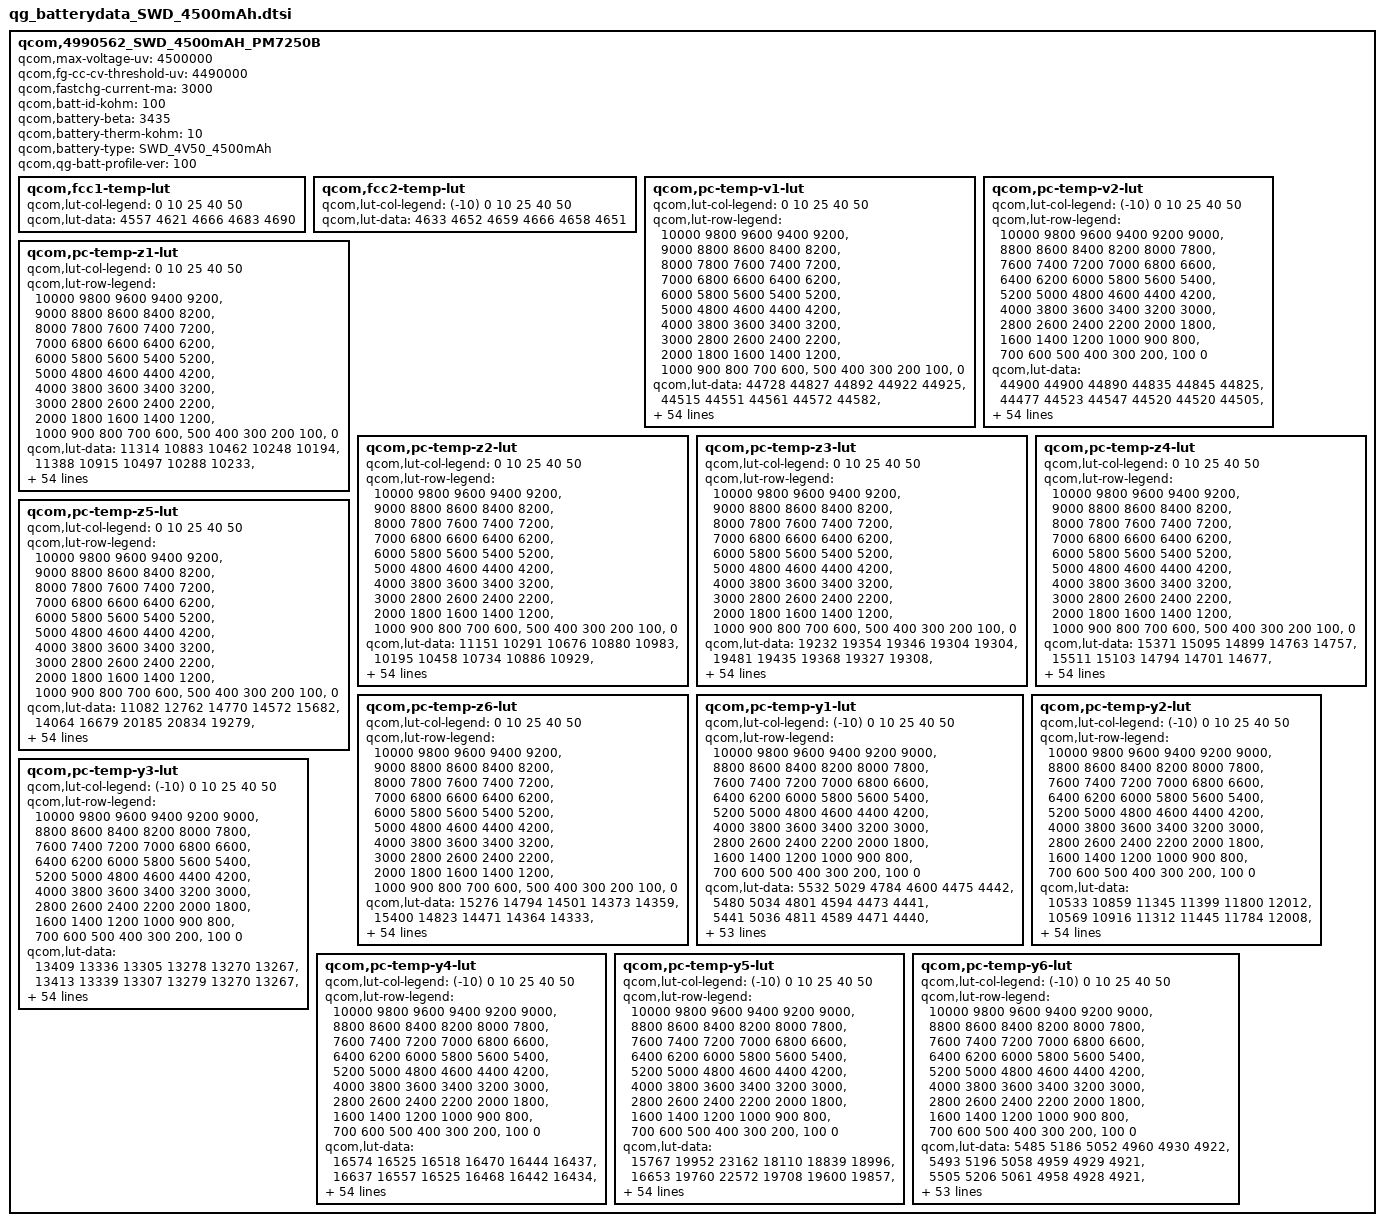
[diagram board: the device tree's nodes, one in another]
/* Copyright (c) 2018, The Linux Foundation. All rights reserved.
 *
 * This program is free software; you can redistribute it and/or modify
 * it under the terms of the GNU General Public License version 2 and
 * only version 2 as published by the Free Software Foundation.
 *
 * This program is distributed in the hope that it will be useful,
 * but WITHOUT ANY WARRANTY; without even the implied warranty of
 * MERCHANTABILITY or FITNESS FOR A PARTICULAR PURPOSE.  See the
 * GNU General Public License for more details.
 */

qcom,4990562_SWD_4500mAH_PM7250B {
    /* 4990562_SWD_4500mAH_PM7250B_averaged_MasterSlave_Jan11th2021 */
    qcom,max-voltage-uv = <4500000>;
    qcom,fg-cc-cv-threshold-uv = <4490000>;
    qcom,fastchg-current-ma = <3000>;
    qcom,batt-id-kohm = <100>;
    qcom,battery-beta = <3435>;
    qcom,battery-therm-kohm = <10>;
    qcom,battery-type = "SWD_4V50_4500mAh";
    qcom,qg-batt-profile-ver = <100>;

	qcom,fcc1-temp-lut {
		qcom,lut-col-legend = <0 10 25 40 50>;
		qcom,lut-data = <4557 4621 4666 4683 4690>;
	};

	qcom,fcc2-temp-lut {
		qcom,lut-col-legend = <(-10) 0 10 25 40 50>;
		qcom,lut-data = <4633 4652 4659 4666 4658 4651>;
	};

	qcom,pc-temp-v1-lut {
		qcom,lut-col-legend = <0 10 25 40 50>;
		qcom,lut-row-legend = <10000 9800 9600 9400 9200>,
			<9000 8800 8600 8400 8200>,
			<8000 7800 7600 7400 7200>,
			<7000 6800 6600 6400 6200>,
			<6000 5800 5600 5400 5200>,
			<5000 4800 4600 4400 4200>,
			<4000 3800 3600 3400 3200>,
			<3000 2800 2600 2400 2200>,
			<2000 1800 1600 1400 1200>,
			<1000 900 800 700 600>,
			<500 400 300 200 100>,
			<0>;
		qcom,lut-data = <44728 44827 44892 44922 44925>,
			<44515 44551 44561 44572 44582>,
			<44325 44352 44340 44336 44342>,
			<44136 44173 44149 44142 44146>,
			<43939 43986 43963 43959 43958>,
			<43734 43786 43763 43761 43762>,
			<43515 43577 43556 43553 43559>,
			<43278 43350 43335 43335 43346>,
			<43034 43109 43095 43102 43116>,
			<42787 42863 42847 42861 42875>,
			<42537 42611 42597 42614 42630>,
			<42291 42359 42345 42361 42380>,
			<42047 42110 42095 42111 42131>,
			<41807 41863 41846 41862 41885>,
			<41574 41623 41603 41618 41643>,
			<41347 41389 41367 41381 41404>,
			<41129 41163 41137 41149 41170>,
			<40922 40948 40916 40924 40943>,
			<40716 40741 40701 40706 40723>,
			<40509 40539 40497 40497 40512>,
			<40297 40346 40310 40308 40320>,
			<40059 40123 40111 40110 40123>,
			<39792 39819 39852 39864 39883>,
			<39560 39529 39571 39589 39614>,
			<39374 39346 39355 39366 39389>,
			<39216 39205 39182 39184 39201>,
			<39089 39071 39032 39027 39039>,
			<38984 38939 38898 38889 38899>,
			<38884 38818 38778 38766 38774>,
			<38782 38709 38667 38651 38657>,
			<38687 38611 38566 38545 38547>,
			<38606 38522 38473 38447 38446>,
			<38533 38442 38387 38356 38352>,
			<38467 38371 38310 38273 38265>,
			<38405 38305 38244 38200 38188>,
			<38350 38247 38186 38135 38117>,
			<38304 38196 38128 38064 38036>,
			<38264 38154 38074 37987 37941>,
			<38204 38097 38009 37902 37840>,
			<38102 38001 37916 37804 37737>,
			<37978 37880 37801 37694 37628>,
			<37842 37750 37676 37571 37499>,
			<37686 37602 37532 37430 37351>,
			<37494 37423 37362 37262 37187>,
			<37327 37250 37199 37110 37041>,
			<37244 37139 37096 37024 36963>,
			<37205 37109 37074 37003 36946>,
			<37171 37085 37055 36988 36931>,
			<37139 37065 37032 36969 36909>,
			<37075 37002 36954 36861 36783>,
			<36793 36716 36654 36536 36448>,
			<36323 36251 36187 36065 35980>,
			<35707 35640 35580 35460 35373>,
			<34871 34806 34757 34625 34543>,
			<33564 33504 33486 33347 33264>,
			<30000 30000 30000 30000 30000>;
	};

	qcom,pc-temp-v2-lut {
		qcom,lut-col-legend = <(-10) 0 10 25 40 50>;
		qcom,lut-row-legend = <10000 9800 9600 9400 9200 9000>,
			<8800 8600 8400 8200 8000 7800>,
			<7600 7400 7200 7000 6800 6600>,
			<6400 6200 6000 5800 5600 5400>,
			<5200 5000 4800 4600 4400 4200>,
			<4000 3800 3600 3400 3200 3000>,
			<2800 2600 2400 2200 2000 1800>,
			<1600 1400 1200 1000 900 800>,
			<700 600 500 400 300 200>,
			<100 0>;
		qcom,lut-data = <44900 44900 44890 44835 44845 44825>,
			<44477 44523 44547 44520 44520 44505>,
			<44126 44209 44256 44246 44238 44226>,
			<43864 43974 44030 44026 44011 44000>,
			<43666 43795 43854 43847 43827 43815>,
			<43464 43609 43669 43658 43635 43623>,
			<43239 43399 43462 43447 43423 43413>,
			<43006 43177 43244 43224 43201 43191>,
			<42767 42943 43011 42990 42968 42960>,
			<42519 42695 42764 42743 42723 42717>,
			<42270 42446 42515 42494 42476 42471>,
			<42019 42194 42263 42243 42227 42223>,
			<41767 41943 42012 41993 41978 41976>,
			<41507 41697 41765 41745 41732 41731>,
			<41253 41455 41521 41501 41490 41490>,
			<41065 41224 41284 41264 41254 41254>,
			<40939 41001 41052 41033 41024 41023>,
			<40779 40788 40826 40808 40801 40800>,
			<40441 40598 40614 40592 40586 40587>,
			<40018 40401 40400 40379 40375 40379>,
			<39724 40139 40163 40166 40172 40177>,
			<39498 39811 39909 39952 39974 39979>,
			<39283 39523 39656 39716 39748 39757>,
			<39064 39284 39395 39429 39460 39474>,
			<38857 39073 39159 39171 39194 39209>,
			<38665 38890 38975 38992 39015 39030>,
			<38487 38729 38819 38845 38871 38886>,
			<38353 38582 38678 38709 38737 38753>,
			<38251 38449 38549 38583 38614 38629>,
			<38168 38324 38431 38469 38501 38514>,
			<38102 38201 38322 38365 38397 38408>,
			<38047 38088 38220 38269 38301 38310>,
			<37992 38008 38126 38178 38213 38221>,
			<37938 37947 38038 38093 38133 38143>,
			<37884 37896 37959 38009 38046 38052>,
			<37825 37856 37888 37930 37948 37938>,
			<37761 37817 37822 37847 37844 37812>,
			<37688 37770 37756 37745 37729 37689>,
			<37607 37715 37690 37633 37608 37565>,
			<37518 37643 37611 37531 37499 37453>,
			<37420 37537 37508 37441 37407 37361>,
			<37307 37405 37387 37330 37295 37250>,
			<37166 37238 37243 37196 37159 37112>,
			<37014 37050 37089 37056 37024 36973>,
			<36885 36886 36923 36915 36880 36833>,
			<36786 36810 36867 36880 36853 36807>,
			<36746 36777 36842 36866 36839 36792>,
			<36707 36740 36817 36841 36818 36772>,
			<36659 36694 36770 36792 36779 36733>,
			<36564 36584 36649 36629 36653 36588>,
			<36330 36270 36324 36251 36283 36194>,
			<35894 35758 35793 35707 35763 35674>,
			<35273 35083 35109 34994 35090 34998>,
			<34428 34147 34168 33993 34168 34081>,
			<33164 32741 32782 32549 32901 32768>,
			<30762 29516 29512 29514 29512 29512>;
	};

	qcom,pc-temp-z1-lut {
		qcom,lut-col-legend = <0 10 25 40 50>;
		qcom,lut-row-legend = <10000 9800 9600 9400 9200>,
			<9000 8800 8600 8400 8200>,
			<8000 7800 7600 7400 7200>,
			<7000 6800 6600 6400 6200>,
			<6000 5800 5600 5400 5200>,
			<5000 4800 4600 4400 4200>,
			<4000 3800 3600 3400 3200>,
			<3000 2800 2600 2400 2200>,
			<2000 1800 1600 1400 1200>,
			<1000 900 800 700 600>,
			<500 400 300 200 100>,
			<0>;
		qcom,lut-data = <11314 10883 10462 10248 10194>,
			<11388 10915 10497 10288 10233>,
			<11383 10916 10487 10285 10231>,
			<11375 10901 10478 10281 10230>,
			<11360 10889 10471 10278 10229>,
			<11335 10882 10464 10275 10227>,
			<11316 10874 10459 10272 10225>,
			<11304 10860 10452 10269 10223>,
			<11293 10842 10446 10266 10221>,
			<11283 10831 10440 10263 10220>,
			<11273 10825 10436 10261 10219>,
			<11262 10821 10432 10259 10218>,
			<11243 10815 10428 10258 10217>,
			<11229 10810 10425 10257 10216>,
			<11227 10810 10422 10256 10215>,
			<11229 10811 10421 10255 10216>,
			<11226 10812 10420 10254 10216>,
			<11218 10805 10420 10254 10216>,
			<11211 10796 10419 10254 10216>,
			<11212 10793 10419 10254 10216>,
			<11215 10795 10420 10255 10217>,
			<11214 10795 10422 10255 10218>,
			<11210 10795 10423 10256 10218>,
			<11208 10795 10424 10257 10220>,
			<11206 10795 10427 10258 10221>,
			<11204 10796 10432 10260 10222>,
			<11205 10798 10437 10262 10223>,
			<11208 10801 10440 10263 10224>,
			<11211 10806 10442 10265 10226>,
			<11216 10814 10445 10267 10227>,
			<11221 10821 10448 10269 10229>,
			<11224 10822 10451 10272 10230>,
			<11225 10816 10454 10274 10232>,
			<11226 10813 10458 10276 10234>,
			<11224 10815 10462 10278 10235>,
			<11222 10819 10467 10281 10237>,
			<11223 10824 10471 10284 10238>,
			<11227 10832 10476 10287 10241>,
			<11231 10838 10481 10289 10242>,
			<11238 10842 10488 10290 10244>,
			<11246 10846 10494 10291 10245>,
			<11252 10851 10496 10293 10246>,
			<11260 10857 10498 10296 10247>,
			<11284 10869 10503 10297 10248>,
			<11286 10875 10511 10298 10248>,
			<11266 10883 10516 10299 10248>,
			<11278 10884 10519 10299 10249>,
			<11266 10875 10520 10299 10249>,
			<11275 10883 10523 10300 10249>,
			<11287 10882 10529 10302 10250>,
			<11280 10896 10533 10305 10252>,
			<11295 10892 10533 10307 10254>,
			<11324 10912 10543 10310 10256>,
			<11329 10924 10554 10315 10261>,
			<11329 10924 10554 10315 10261>,
			<11329 10924 10554 10315 10261>;
	};

	qcom,pc-temp-z2-lut {
		qcom,lut-col-legend = <0 10 25 40 50>;
		qcom,lut-row-legend = <10000 9800 9600 9400 9200>,
			<9000 8800 8600 8400 8200>,
			<8000 7800 7600 7400 7200>,
			<7000 6800 6600 6400 6200>,
			<6000 5800 5600 5400 5200>,
			<5000 4800 4600 4400 4200>,
			<4000 3800 3600 3400 3200>,
			<3000 2800 2600 2400 2200>,
			<2000 1800 1600 1400 1200>,
			<1000 900 800 700 600>,
			<500 400 300 200 100>,
			<0>;
		qcom,lut-data = <11151 10291 10676 10880 10983>,
			<10195 10458 10734 10886 10929>,
			<10293 10494 10876 11073 11007>,
			<10376 10557 10843 10988 10957>,
			<10380 10580 10796 10851 10934>,
			<10378 10546 10757 10815 10935>,
			<10370 10501 10717 10805 10952>,
			<10343 10471 10708 10803 10961>,
			<10316 10446 10719 10803 10948>,
			<10295 10441 10729 10803 10934>,
			<10279 10460 10727 10809 10939>,
			<10280 10479 10722 10824 10956>,
			<10303 10487 10725 10839 10965>,
			<10324 10492 10734 10859 10964>,
			<10333 10500 10738 10878 10965>,
			<10340 10509 10721 10895 10992>,
			<10350 10516 10702 10910 11034>,
			<10364 10519 10704 10921 11054>,
			<10374 10522 10714 10937 11067>,
			<10380 10527 10718 10944 11080>,
			<10385 10535 10712 10945 11107>,
			<10401 10538 10706 10948 11130>,
			<10436 10512 10713 10959 11112>,
			<10452 10484 10728 10975 11050>,
			<10409 10501 10750 10965 10977>,
			<10357 10546 10795 10860 10863>,
			<10356 10559 10817 10776 10795>,
			<10373 10542 10770 10758 10805>,
			<10386 10527 10709 10748 10825>,
			<10394 10523 10699 10752 10843>,
			<10401 10521 10698 10779 10872>,
			<10408 10524 10701 10808 10909>,
			<10415 10545 10735 10840 10962>,
			<10422 10567 10777 10876 11024>,
			<10433 10582 10806 10920 11093>,
			<10443 10594 10831 10969 11168>,
			<10448 10599 10843 11007 11218>,
			<10451 10600 10850 11035 11257>,
			<10456 10604 10859 11058 11275>,
			<10470 10640 10905 11088 11267>,
			<10480 10676 10960 11115 11250>,
			<10470 10662 10954 11109 11230>,
			<10455 10627 10916 11072 11192>,
			<10463 10629 10912 11025 11154>,
			<10503 10662 10898 11004 11120>,
			<18534 10717 10868 11084 11122>,
			<17987 10695 10856 11078 11184>,
			<19085 10681 10847 11085 11246>,
			<21067 10688 10824 11205 11348>,
			<20840 10749 10864 11045 11109>,
			<19707 10825 10798 10865 10944>,
			<16740 10870 10737 10838 10919>,
			<16893 10918 10678 10799 10858>,
			<15715 10893 10634 10727 10805>,
			<15715 10893 10634 10727 10805>,
			<15715 10893 10634 10727 10805>;
	};

	qcom,pc-temp-z3-lut {
		qcom,lut-col-legend = <0 10 25 40 50>;
		qcom,lut-row-legend = <10000 9800 9600 9400 9200>,
			<9000 8800 8600 8400 8200>,
			<8000 7800 7600 7400 7200>,
			<7000 6800 6600 6400 6200>,
			<6000 5800 5600 5400 5200>,
			<5000 4800 4600 4400 4200>,
			<4000 3800 3600 3400 3200>,
			<3000 2800 2600 2400 2200>,
			<2000 1800 1600 1400 1200>,
			<1000 900 800 700 600>,
			<500 400 300 200 100>,
			<0>;
		qcom,lut-data = <19232 19354 19346 19304 19304>,
			<19481 19435 19368 19327 19308>,
			<19529 19467 19389 19344 19322>,
			<19567 19481 19397 19345 19327>,
			<19588 19489 19399 19345 19330>,
			<19602 19495 19397 19345 19329>,
			<19612 19498 19392 19343 19325>,
			<19618 19499 19390 19341 19322>,
			<19622 19499 19389 19337 19322>,
			<19622 19498 19387 19334 19321>,
			<19622 19489 19384 19333 19321>,
			<19620 19480 19378 19332 19320>,
			<19610 19478 19375 19331 19319>,
			<19600 19475 19373 19330 19315>,
			<19595 19473 19370 19329 19311>,
			<19591 19469 19366 19325 19310>,
			<19586 19465 19362 19320 19310>,
			<19580 19462 19360 19318 19309>,
			<19575 19458 19358 19318 19308>,
			<19572 19454 19356 19317 19306>,
			<19570 19450 19355 19315 19304>,
			<19575 19449 19353 19314 19302>,
			<19598 19459 19353 19317 19307>,
			<19609 19470 19354 19326 19319>,
			<19594 19467 19359 19333 19326>,
			<19577 19456 19379 19340 19329>,
			<19576 19454 19391 19344 19331>,
			<19578 19470 19391 19343 19327>,
			<19579 19483 19391 19340 19321>,
			<19579 19481 19389 19337 19318>,
			<19579 19475 19383 19333 19316>,
			<19577 19469 19379 19330 19314>,
			<19571 19464 19375 19327 19312>,
			<19566 19460 19372 19324 19309>,
			<19563 19458 19369 19321 19305>,
			<19560 19456 19366 19318 19301>,
			<19558 19454 19365 19318 19300>,
			<19555 19453 19364 19319 19304>,
			<19551 19451 19364 19320 19307>,
			<19544 19446 19363 19323 19310>,
			<19537 19440 19361 19326 19313>,
			<19532 19436 19360 19326 19314>,
			<19528 19432 19359 19323 19315>,
			<19521 19427 19357 19324 19315>,
			<19459 19417 19351 19324 19314>,
			<19264 19400 19343 19313 19305>,
			<19257 19400 19339 19313 19300>,
			<19256 19400 19336 19309 19295>,
			<19256 19390 19334 19302 19294>,
			<19256 19383 19337 19316 19303>,
			<19256 19375 19348 19322 19309>,
			<19257 19358 19353 19323 19307>,
			<19257 19342 19356 19321 19307>,
			<19257 19337 19356 19325 19309>,
			<19257 19337 19356 19325 19309>,
			<19257 19337 19356 19325 19309>;
	};

	qcom,pc-temp-z4-lut {
		qcom,lut-col-legend = <0 10 25 40 50>;
		qcom,lut-row-legend = <10000 9800 9600 9400 9200>,
			<9000 8800 8600 8400 8200>,
			<8000 7800 7600 7400 7200>,
			<7000 6800 6600 6400 6200>,
			<6000 5800 5600 5400 5200>,
			<5000 4800 4600 4400 4200>,
			<4000 3800 3600 3400 3200>,
			<3000 2800 2600 2400 2200>,
			<2000 1800 1600 1400 1200>,
			<1000 900 800 700 600>,
			<500 400 300 200 100>,
			<0>;
		qcom,lut-data = <15371 15095 14899 14763 14757>,
			<15511 15103 14794 14701 14677>,
			<15437 15206 14893 14753 14708>,
			<15335 15098 14859 14743 14704>,
			<15241 15005 14810 14724 14689>,
			<15142 14942 14777 14710 14681>,
			<15064 14889 14751 14698 14677>,
			<15002 14845 14734 14690 14673>,
			<14948 14806 14725 14686 14668>,
			<14900 14784 14717 14683 14664>,
			<14858 14771 14711 14678 14660>,
			<14827 14761 14706 14672 14655>,
			<14802 14753 14700 14666 14652>,
			<14788 14746 14693 14660 14650>,
			<14783 14741 14688 14656 14648>,
			<14781 14737 14684 14652 14643>,
			<14778 14734 14681 14650 14637>,
			<14775 14731 14677 14645 14632>,
			<14773 14729 14673 14639 14628>,
			<14781 14730 14671 14636 14625>,
			<14797 14734 14671 14635 14623>,
			<14814 14743 14671 14634 14622>,
			<14837 14797 14707 14652 14633>,
			<14858 14850 14772 14693 14661>,
			<14879 14851 14781 14703 14669>,
			<14895 14845 14757 14694 14665>,
			<14888 14833 14735 14683 14660>,
			<14860 14801 14721 14676 14658>,
			<14840 14774 14711 14669 14655>,
			<14830 14767 14705 14664 14652>,
			<14823 14762 14700 14660 14647>,
			<14820 14761 14698 14657 14643>,
			<14819 14761 14697 14653 14639>,
			<14818 14761 14696 14651 14637>,
			<14819 14763 14696 14651 14636>,
			<14820 14765 14698 14651 14636>,
			<14818 14765 14700 14652 14638>,
			<14811 14762 14705 14664 14648>,
			<14804 14758 14708 14671 14655>,
			<14797 14755 14708 14669 14652>,
			<14789 14751 14707 14665 14646>,
			<14771 14740 14701 14660 14642>,
			<14748 14720 14687 14654 14639>,
			<14725 14704 14678 14650 14638>,
			<14738 14683 14669 14646 14635>,
			<14877 14657 14651 14636 14626>,
			<14879 14647 14644 14628 14623>,
			<14875 14638 14634 14621 14617>,
			<14870 14640 14628 14619 14611>,
			<14865 14647 14632 14616 14612>,
			<14871 14663 14628 14616 14615>,
			<14872 14683 14623 14616 14615>,
			<14875 14701 14621 14616 14615>,
			<14878 14709 14620 14615 14614>,
			<14878 14709 14620 14615 14614>,
			<14878 14709 14620 14615 14614>;
	};

	qcom,pc-temp-z5-lut {
		qcom,lut-col-legend = <0 10 25 40 50>;
		qcom,lut-row-legend = <10000 9800 9600 9400 9200>,
			<9000 8800 8600 8400 8200>,
			<8000 7800 7600 7400 7200>,
			<7000 6800 6600 6400 6200>,
			<6000 5800 5600 5400 5200>,
			<5000 4800 4600 4400 4200>,
			<4000 3800 3600 3400 3200>,
			<3000 2800 2600 2400 2200>,
			<2000 1800 1600 1400 1200>,
			<1000 900 800 700 600>,
			<500 400 300 200 100>,
			<0>;
		qcom,lut-data = <11082 12762 14770 14572 15682>,
			<14064 16679 20185 20834 19279>,
			<15604 17011 19162 21475 21898>,
			<17161 18402 19747 21447 22927>,
			<18375 19636 20487 21399 24562>,
			<19457 20469 20818 21619 24708>,
			<20570 21295 21095 22456 24096>,
			<21680 22407 21379 22804 23787>,
			<22895 23647 21854 22233 24089>,
			<24377 24338 22147 21665 24614>,
			<26033 24645 21990 21878 25261>,
			<27691 24978 21728 22555 26058>,
			<29458 25667 21829 23233 26157>,
			<30845 26537 22486 24054 24864>,
			<31792 27140 22876 24490 23860>,
			<32477 27619 22692 23858 24514>,
			<32680 27895 22473 22928 25982>,
			<32632 28029 22800 23207 27403>,
			<32688 28113 23633 24850 29013>,
			<33271 27833 24188 26008 30040>,
			<34406 26803 24626 26584 30696>,
			<37071 26465 24875 26894 31113>,
			<43157 30008 23316 25063 29107>,
			<45984 33721 20517 20895 24078>,
			<39465 31168 20046 19818 22599>,
			<31584 24178 20648 20354 23026>,
			<30890 22213 21542 21118 23345>,
			<31412 25738 23142 22090 23068>,
			<32289 29891 25167 23249 22619>,
			<35097 32455 26784 24218 22863>,
			<38249 34600 28243 25080 24439>,
			<39686 36149 30046 26195 26072>,
			<40637 37388 32790 28119 27734>,
			<41286 38376 35050 30002 28979>,
			<41853 39329 36014 31159 29135>,
			<42183 40046 36631 32038 28970>,
			<42129 40058 36632 32015 28663>,
			<41904 39675 35847 30433 27747>,
			<41572 39083 34779 29329 27134>,
			<40798 37305 32555 30095 29153>,
			<40161 35305 30232 31237 33055>,
			<40032 34497 30204 31248 36062>,
			<40019 33981 30854 30782 38575>,
			<40374 33008 29499 31166 37341>,
			<35783 33395 27535 30619 34596>,
			<12780 34559 28883 25851 28964>,
			<11535 36467 28955 29909 26875>,
			<11478 38567 31451 34709 29504>,
			<11422 30454 33206 30773 35300>,
			<11444 25106 29237 42487 39318>,
			<11476 20294 32134 46320 44672>,
			<11440 16690 35995 45816 38962>,
			<11396 14817 39585 37615 36669>,
			<11326 14298 37749 44630 36347>,
			<11326 14298 37749 44630 36347>,
			<11326 14298 37749 44630 36347>;
	};

	qcom,pc-temp-z6-lut {
		qcom,lut-col-legend = <0 10 25 40 50>;
		qcom,lut-row-legend = <10000 9800 9600 9400 9200>,
			<9000 8800 8600 8400 8200>,
			<8000 7800 7600 7400 7200>,
			<7000 6800 6600 6400 6200>,
			<6000 5800 5600 5400 5200>,
			<5000 4800 4600 4400 4200>,
			<4000 3800 3600 3400 3200>,
			<3000 2800 2600 2400 2200>,
			<2000 1800 1600 1400 1200>,
			<1000 900 800 700 600>,
			<500 400 300 200 100>,
			<0>;
		qcom,lut-data = <15276 14794 14501 14373 14359>,
			<15400 14823 14471 14364 14333>,
			<15345 14869 14520 14394 14354>,
			<15270 14815 14506 14390 14354>,
			<15204 14766 14485 14381 14349>,
			<15136 14729 14468 14374 14345>,
			<15077 14697 14452 14368 14341>,
			<15025 14669 14442 14362 14337>,
			<14980 14645 14436 14358 14335>,
			<14939 14626 14431 14355 14333>,
			<14902 14611 14425 14351 14330>,
			<14872 14599 14419 14348 14328>,
			<14846 14591 14414 14345 14325>,
			<14828 14584 14409 14342 14322>,
			<14820 14578 14405 14338 14319>,
			<14815 14573 14400 14335 14316>,
			<14808 14569 14397 14331 14313>,
			<14801 14564 14393 14328 14311>,
			<14797 14561 14391 14325 14308>,
			<14799 14560 14389 14323 14306>,
			<14803 14559 14388 14321 14304>,
			<14812 14559 14388 14321 14303>,
			<14832 14588 14404 14331 14310>,
			<14844 14618 14433 14354 14330>,
			<14846 14618 14439 14361 14336>,
			<14847 14612 14439 14361 14337>,
			<14843 14607 14439 14360 14337>,
			<14835 14603 14436 14357 14334>,
			<14829 14599 14430 14353 14330>,
			<14826 14595 14426 14349 14327>,
			<14824 14592 14422 14345 14324>,
			<14822 14590 14419 14342 14321>,
			<14821 14588 14417 14339 14318>,
			<14820 14587 14416 14337 14316>,
			<14821 14588 14416 14335 14313>,
			<14822 14590 14416 14334 14311>,
			<14823 14591 14416 14335 14312>,
			<14823 14592 14420 14341 14318>,
			<14824 14592 14422 14345 14323>,
			<14824 14592 14422 14345 14323>,
			<14824 14591 14422 14345 14322>,
			<14821 14588 14420 14344 14321>,
			<14815 14582 14415 14340 14320>,
			<14814 14577 14411 14339 14320>,
			<14801 14569 14405 14337 14319>,
			<14774 14554 14395 14328 14310>,
			<14772 14551 14390 14324 14306>,
			<14774 14548 14384 14319 14301>,
			<14777 14546 14382 14314 14298>,
			<14780 14550 14386 14320 14303>,
			<14789 14557 14392 14325 14308>,
			<14796 14561 14394 14326 14308>,
			<14808 14566 14396 14326 14309>,
			<14823 14574 14399 14329 14311>,
			<14823 14574 14399 14329 14311>,
			<14823 14574 14399 14329 14311>;
	};

	qcom,pc-temp-y1-lut {
		qcom,lut-col-legend = <(-10) 0 10 25 40 50>;
		qcom,lut-row-legend = <10000 9800 9600 9400 9200 9000>,
			<8800 8600 8400 8200 8000 7800>,
			<7600 7400 7200 7000 6800 6600>,
			<6400 6200 6000 5800 5600 5400>,
			<5200 5000 4800 4600 4400 4200>,
			<4000 3800 3600 3400 3200 3000>,
			<2800 2600 2400 2200 2000 1800>,
			<1600 1400 1200 1000 900 800>,
			<700 600 500 400 300 200>,
			<100 0>;
		qcom,lut-data = <5532 5029 4784 4600 4475 4442>,
			<5480 5034 4801 4594 4473 4441>,
			<5441 5036 4811 4589 4471 4440>,
			<5414 5036 4816 4584 4470 4439>,
			<5398 5035 4818 4580 4468 4439>,
			<5394 5033 4818 4576 4466 4438>,
			<5409 5028 4811 4572 4464 4437>,
			<5427 5024 4801 4569 4463 4436>,
			<5429 5026 4795 4566 4461 4435>,
			<5424 5031 4790 4563 4459 4434>,
			<5422 5032 4789 4560 4458 4433>,
			<5426 5030 4792 4558 4457 4431>,
			<5429 5028 4794 4555 4457 4431>,
			<5422 5023 4788 4553 4456 4431>,
			<5409 5017 4778 4552 4454 4431>,
			<5406 5016 4776 4550 4454 4431>,
			<5409 5019 4777 4550 4453 4431>,
			<5412 5020 4777 4549 4453 4430>,
			<5417 5019 4772 4549 4453 4431>,
			<5423 5019 4766 4549 4453 4431>,
			<5421 5021 4766 4549 4453 4431>,
			<5412 5025 4767 4550 4453 4431>,
			<5408 5028 4768 4551 4453 4431>,
			<5413 5026 4772 4552 4454 4431>,
			<5421 5025 4776 4553 4455 4432>,
			<5428 5028 4777 4555 4455 4432>,
			<5436 5032 4779 4556 4456 4432>,
			<5437 5034 4779 4558 4456 4433>,
			<5425 5035 4782 4561 4457 4433>,
			<5414 5035 4784 4563 4458 4434>,
			<5418 5042 4786 4565 4459 4435>,
			<5426 5051 4789 4566 4460 4436>,
			<5428 5052 4791 4568 4461 4437>,
			<5427 5050 4794 4571 4463 4438>,
			<5427 5047 4798 4573 4464 4439>,
			<5421 5043 4801 4576 4465 4440>,
			<5412 5040 4804 4579 4466 4440>,
			<5413 5044 4805 4582 4467 4441>,
			<5419 5054 4803 4586 4468 4441>,
			<5423 5056 4804 4588 4469 4442>,
			<5428 5048 4810 4589 4470 4444>,
			<5430 5047 4812 4590 4471 4444>,
			<5426 5053 4815 4591 4472 4444>,
			<5450 5053 4817 4597 4473 4445>,
			<5439 5055 4832 4598 4474 4446>,
			<5458 5087 4827 4600 4475 4446>,
			<5434 5063 4843 4601 4476 4447>,
			<5448 5074 4840 4602 4476 4447>,
			<5436 5062 4848 4602 4476 4447>,
			<5450 5057 4848 4605 4476 4447>,
			<5484 5065 4840 4604 4477 4448>,
			<5496 5081 4848 4609 4479 4449>,
			<5544 5090 4862 4615 4480 4451>,
			<5574 5101 4865 4623 4482 4453>,
			<5574 5101 4865 4623 4482 4453>,
			<5574 5101 4865 4623 4482 4453>;
	};

	qcom,pc-temp-y2-lut {
		qcom,lut-col-legend = <(-10) 0 10 25 40 50>;
		qcom,lut-row-legend = <10000 9800 9600 9400 9200 9000>,
			<8800 8600 8400 8200 8000 7800>,
			<7600 7400 7200 7000 6800 6600>,
			<6400 6200 6000 5800 5600 5400>,
			<5200 5000 4800 4600 4400 4200>,
			<4000 3800 3600 3400 3200 3000>,
			<2800 2600 2400 2200 2000 1800>,
			<1600 1400 1200 1000 900 800>,
			<700 600 500 400 300 200>,
			<100 0>;
		qcom,lut-data = <10533 10859 11345 11399 11800 12012>,
			<10569 10916 11312 11445 11784 12008>,
			<10645 10968 11280 11467 11757 11982>,
			<10731 11012 11250 11471 11723 11941>,
			<10800 11040 11224 11463 11687 11887>,
			<10823 11048 11202 11448 11652 11826>,
			<10822 11036 11186 11377 11578 11739>,
			<10819 11018 11169 11298 11507 11658>,
			<10819 10999 11146 11270 11492 11611>,
			<10821 10976 11117 11254 11485 11572>,
			<10820 10964 11094 11246 11472 11559>,
			<10803 10957 11073 11246 11427 11557>,
			<10790 10954 11062 11250 11394 11555>,
			<10830 10969 11071 11264 11407 11539>,
			<10916 11005 11095 11283 11432 11510>,
			<10943 11040 11120 11298 11438 11496>,
			<10925 11077 11154 11307 11430 11487>,
			<10915 11115 11197 11323 11426 11482>,
			<10951 11161 11271 11368 11433 11478>,
			<10995 11198 11344 11438 11450 11474>,
			<10997 11199 11374 11543 11522 11485>,
			<10975 11188 11393 11684 11696 11534>,
			<10953 11177 11395 11716 11779 11603>,
			<10937 11162 11359 11599 11779 11768>,
			<10914 11149 11326 11500 11770 11909>,
			<10802 11144 11330 11500 11779 11912>,
			<10551 11139 11341 11510 11797 11887>,
			<10414 11138 11352 11526 11806 11890>,
			<10357 11138 11367 11555 11794 11932>,
			<10326 11142 11378 11581 11790 11985>,
			<10163 11157 11385 11612 11808 12051>,
			<9849 11174 11390 11645 11835 12116>,
			<9749 11175 11393 11670 11863 12134>,
			<9728 11169 11395 11695 11902 12133>,
			<9713 11159 11395 11702 11923 12128>,
			<9700 11131 11392 11680 11923 12123>,
			<9690 11092 11386 11653 11918 12116>,
			<9684 11052 11372 11636 11927 12095>,
			<9679 11006 11343 11624 11948 12060>,
			<9676 10948 11313 11624 11948 12051>,
			<9674 10869 11276 11635 11909 12072>,
			<9672 10704 11221 11633 11885 12058>,
			<9670 10322 11137 11625 11873 11939>,
			<9669 9934 11090 11599 11845 11907>,
			<9667 9819 10987 11559 11833 11978>,
			<9665 9731 10912 11522 11737 11837>,
			<9664 9714 10859 11514 11652 11746>,
			<9663 9695 10828 11483 11653 11696>,
			<9662 9686 10760 11399 11567 11610>,
			<9661 9679 10692 11402 11524 11627>,
			<9658 9673 10621 11371 11522 11598>,
			<9655 9668 10443 11294 11484 11583>,
			<9651 9662 10203 11256 11401 11442>,
			<9650 9655 9933 11208 11296 11353>,
			<9650 9655 9933 11208 11296 11353>,
			<9650 9655 9933 11208 11296 11353>;
	};

	qcom,pc-temp-y3-lut {
		qcom,lut-col-legend = <(-10) 0 10 25 40 50>;
		qcom,lut-row-legend = <10000 9800 9600 9400 9200 9000>,
			<8800 8600 8400 8200 8000 7800>,
			<7600 7400 7200 7000 6800 6600>,
			<6400 6200 6000 5800 5600 5400>,
			<5200 5000 4800 4600 4400 4200>,
			<4000 3800 3600 3400 3200 3000>,
			<2800 2600 2400 2200 2000 1800>,
			<1600 1400 1200 1000 900 800>,
			<700 600 500 400 300 200>,
			<100 0>;
		qcom,lut-data = <13409 13336 13305 13278 13270 13267>,
			<13413 13339 13307 13279 13270 13267>,
			<13417 13343 13308 13280 13270 13267>,
			<13421 13346 13310 13281 13270 13268>,
			<13424 13349 13311 13282 13271 13268>,
			<13426 13351 13312 13282 13271 13269>,
			<13427 13353 13314 13283 13272 13269>,
			<13428 13354 13315 13283 13272 13270>,
			<13430 13355 13315 13283 13273 13270>,
			<13434 13356 13315 13283 13274 13271>,
			<13434 13357 13316 13284 13274 13271>,
			<13431 13359 13316 13285 13275 13272>,
			<13425 13360 13317 13285 13276 13272>,
			<13417 13360 13318 13285 13276 13273>,
			<13407 13359 13318 13286 13276 13273>,
			<13401 13356 13318 13286 13277 13273>,
			<13396 13351 13318 13289 13279 13273>,
			<13392 13347 13318 13290 13280 13274>,
			<13389 13345 13315 13291 13279 13275>,
			<13385 13343 13311 13292 13279 13276>,
			<13381 13340 13310 13292 13279 13277>,
			<13375 13336 13310 13291 13281 13277>,
			<13370 13332 13309 13290 13281 13277>,
			<13366 13328 13306 13285 13276 13273>,
			<13362 13326 13302 13280 13271 13269>,
			<13356 13324 13301 13280 13270 13268>,
			<13347 13323 13300 13280 13270 13268>,
			<13343 13321 13300 13280 13270 13268>,
			<13337 13320 13299 13280 13270 13268>,
			<13333 13318 13299 13279 13271 13268>,
			<13338 13315 13299 13280 13271 13268>,
			<13348 13313 13298 13280 13271 13268>,
			<13359 13312 13298 13280 13271 13268>,
			<13371 13312 13297 13280 13271 13269>,
			<13386 13313 13296 13280 13271 13269>,
			<13403 13315 13296 13280 13271 13268>,
			<13423 13319 13296 13279 13271 13268>,
			<13446 13322 13296 13278 13270 13267>,
			<13473 13324 13297 13277 13269 13268>,
			<13503 13327 13297 13276 13269 13268>,
			<13536 13330 13297 13275 13270 13269>,
			<13575 13333 13298 13275 13270 13269>,
			<13623 13335 13300 13275 13270 13269>,
			<13676 13336 13301 13277 13271 13269>,
			<13707 13345 13299 13276 13269 13268>,
			<13806 13371 13304 13277 13271 13270>,
			<13869 13386 13306 13280 13272 13270>,
			<13950 13404 13311 13281 13273 13271>,
			<14052 13436 13316 13285 13274 13272>,
			<14177 13481 13322 13286 13275 13271>,
			<14391 13528 13326 13285 13274 13271>,
			<14977 13627 13332 13286 13274 13271>,
			<16247 13849 13348 13288 13274 13271>,
			<18865 14444 13386 13292 13276 13272>,
			<18865 14444 13386 13292 13276 13272>,
			<18865 14444 13386 13292 13276 13272>;
	};

	qcom,pc-temp-y4-lut {
		qcom,lut-col-legend = <(-10) 0 10 25 40 50>;
		qcom,lut-row-legend = <10000 9800 9600 9400 9200 9000>,
			<8800 8600 8400 8200 8000 7800>,
			<7600 7400 7200 7000 6800 6600>,
			<6400 6200 6000 5800 5600 5400>,
			<5200 5000 4800 4600 4400 4200>,
			<4000 3800 3600 3400 3200 3000>,
			<2800 2600 2400 2200 2000 1800>,
			<1600 1400 1200 1000 900 800>,
			<700 600 500 400 300 200>,
			<100 0>;
		qcom,lut-data = <16574 16525 16518 16470 16444 16437>,
			<16637 16557 16525 16468 16442 16434>,
			<16732 16611 16540 16465 16439 16431>,
			<16834 16672 16557 16462 16436 16429>,
			<16915 16720 16570 16460 16434 16427>,
			<16951 16738 16575 16459 16432 16425>,
			<16962 16742 16575 16459 16431 16424>,
			<16968 16744 16575 16459 16431 16424>,
			<16961 16740 16572 16460 16431 16424>,
			<16941 16726 16563 16461 16431 16424>,
			<16934 16716 16558 16462 16431 16424>,
			<16938 16708 16556 16464 16432 16424>,
			<16946 16703 16555 16466 16434 16425>,
			<16959 16709 16557 16470 16436 16426>,
			<16984 16723 16563 16476 16440 16429>,
			<17031 16745 16572 16481 16442 16431>,
			<17147 16788 16588 16486 16444 16435>,
			<17217 16831 16609 16494 16447 16438>,
			<17082 16877 16656 16509 16454 16442>,
			<16867 16911 16699 16527 16466 16447>,
			<16794 16880 16695 16550 16484 16458>,
			<16767 16760 16664 16575 16508 16479>,
			<16736 16674 16627 16577 16514 16485>,
			<16688 16630 16570 16518 16476 16458>,
			<16641 16599 16524 16465 16441 16432>,
			<16607 16579 16511 16459 16438 16429>,
			<16577 16564 16503 16455 16436 16428>,
			<16569 16552 16501 16455 16436 16428>,
			<16581 16541 16500 16457 16438 16430>,
			<16595 16529 16500 16461 16440 16432>,
			<16604 16509 16500 16466 16444 16435>,
			<16615 16489 16501 16472 16449 16439>,
			<16622 16487 16501 16478 16456 16444>,
			<16630 16491 16502 16484 16464 16451>,
			<16638 16498 16502 16486 16466 16453>,
			<16648 16513 16497 16486 16462 16447>,
			<16658 16534 16493 16486 16455 16438>,
			<16666 16557 16493 16475 16448 16434>,
			<16673 16582 16493 16451 16440 16432>,
			<16677 16590 16493 16445 16437 16431>,
			<16678 16589 16493 16445 16436 16430>,
			<16678 16585 16494 16445 16434 16429>,
			<16661 16573 16500 16444 16430 16426>,
			<16644 16576 16508 16445 16429 16428>,
			<16622 16558 16491 16435 16420 16417>,
			<16630 16571 16505 16446 16426 16421>,
			<16641 16581 16518 16451 16429 16424>,
			<16658 16602 16534 16458 16432 16430>,
			<16685 16629 16554 16468 16444 16448>,
			<16717 16654 16572 16467 16450 16455>,
			<16737 16659 16578 16468 16430 16426>,
			<16846 16668 16589 16478 16432 16429>,
			<17235 16718 16628 16500 16443 16440>,
			<18614 17023 16696 16555 16478 16476>,
			<18614 17023 16696 16555 16478 16476>,
			<18614 17023 16696 16555 16478 16476>;
	};

	qcom,pc-temp-y5-lut {
		qcom,lut-col-legend = <(-10) 0 10 25 40 50>;
		qcom,lut-row-legend = <10000 9800 9600 9400 9200 9000>,
			<8800 8600 8400 8200 8000 7800>,
			<7600 7400 7200 7000 6800 6600>,
			<6400 6200 6000 5800 5600 5400>,
			<5200 5000 4800 4600 4400 4200>,
			<4000 3800 3600 3400 3200 3000>,
			<2800 2600 2400 2200 2000 1800>,
			<1600 1400 1200 1000 900 800>,
			<700 600 500 400 300 200>,
			<100 0>;
		qcom,lut-data = <15767 19952 23162 18110 18839 18996>,
			<16653 19760 22572 19708 19600 19857>,
			<17538 19595 21950 20653 20283 20995>,
			<18360 19470 21364 21110 20830 22170>,
			<19060 19396 20880 21249 21182 23142>,
			<19580 19395 20563 21213 21278 23678>,
			<19977 19656 20393 20432 21118 24018>,
			<20271 19931 20237 19342 20946 24230>,
			<20462 19901 19979 18610 20945 24224>,
			<20604 19739 19628 17966 20959 24150>,
			<20585 19546 19263 17537 20895 24026>,
			<19778 19305 18887 17264 20541 23776>,
			<18635 18965 18460 17007 20034 23399>,
			<17405 18320 17907 16504 19237 22737>,
			<16169 17405 17262 15940 18374 21764>,
			<16268 16572 16621 15874 18430 20728>,
			<18701 15690 15918 16026 19425 19469>,
			<20778 15317 15575 16107 19956 18890>,
			<21414 17289 15521 15866 18458 19141>,
			<21872 20241 15515 15589 16637 19463>,
			<22497 21647 16770 16379 16812 19429>,
			<23277 22560 20632 18725 17960 19204>,
			<23715 23157 22765 20058 18814 19161>,
			<23911 23537 23485 20576 19318 20133>,
			<24030 23853 23931 21013 19710 21249>,
			<22980 24252 24240 21632 20097 21839>,
			<19933 24662 24474 22210 20453 22442>,
			<18113 24871 24635 22167 20484 22444>,
			<15409 24978 24909 21417 20178 21742>,
			<13253 24909 25062 21005 19836 20837>,
			<13117 23634 25013 21287 19547 19686>,
			<13179 21755 24944 21626 19246 18618>,
			<13349 20969 24942 21678 18961 18571>,
			<13722 20163 24978 21669 18671 19037>,
			<14095 19966 25056 21709 18620 19505>,
			<14387 20744 25578 22147 19826 19975>,
			<14627 21637 26077 22671 21109 20512>,
			<14747 22007 25883 22917 21121 21119>,
			<14818 22279 25152 22814 20786 21883>,
			<14894 22519 24014 21760 20677 22592>,
			<15059 22916 21761 19073 20794 23824>,
			<15111 22595 20869 18473 21199 25661>,
			<14870 19952 20727 18848 22399 28505>,
			<14220 15765 19704 20458 23956 28183>,
			<13786 14946 20165 21799 27403 32348>,
			<13568 15317 20668 20546 23660 28020>,
			<13375 14938 19562 21322 22447 27046>,
			<13505 14401 19351 19909 22558 28292>,
			<13796 14447 18394 21284 23305 26381>,
			<13986 14872 18698 24756 25892 23955>,
			<13988 14762 19747 25813 29275 33405>,
			<12615 14884 19232 25785 30346 32686>,
			<10951 14520 18610 25452 28926 29756>,
			<9814 12565 18004 25080 27753 28814>,
			<9814 12565 18004 25080 27753 28814>,
			<9814 12565 18004 25080 27753 28814>;
	};

	qcom,pc-temp-y6-lut {
		qcom,lut-col-legend = <(-10) 0 10 25 40 50>;
		qcom,lut-row-legend = <10000 9800 9600 9400 9200 9000>,
			<8800 8600 8400 8200 8000 7800>,
			<7600 7400 7200 7000 6800 6600>,
			<6400 6200 6000 5800 5600 5400>,
			<5200 5000 4800 4600 4400 4200>,
			<4000 3800 3600 3400 3200 3000>,
			<2800 2600 2400 2200 2000 1800>,
			<1600 1400 1200 1000 900 800>,
			<700 600 500 400 300 200>,
			<100 0>;
		qcom,lut-data = <5485 5186 5052 4960 4930 4922>,
			<5493 5196 5058 4959 4929 4921>,
			<5505 5206 5061 4958 4928 4921>,
			<5516 5215 5062 4957 4928 4920>,
			<5525 5222 5063 4957 4927 4920>,
			<5528 5224 5063 4956 4927 4920>,
			<5527 5222 5062 4956 4927 4920>,
			<5525 5219 5059 4956 4927 4920>,
			<5521 5215 5056 4956 4928 4921>,
			<5514 5209 5052 4956 4928 4921>,
			<5508 5205 5050 4956 4928 4921>,
			<5503 5200 5048 4957 4929 4922>,
			<5499 5197 5047 4957 4930 4922>,
			<5497 5198 5047 4959 4931 4923>,
			<5494 5199 5048 4960 4932 4924>,
			<5499 5201 5049 4962 4933 4925>,
			<5531 5208 5052 4965 4935 4926>,
			<5552 5217 5057 4968 4937 4927>,
			<5515 5228 5068 4973 4939 4929>,
			<5456 5237 5077 4978 4941 4931>,
			<5435 5228 5076 4985 4946 4935>,
			<5427 5191 5067 4991 4954 4941>,
			<5419 5165 5055 4991 4956 4942>,
			<5408 5151 5037 4971 4941 4932>,
			<5398 5141 5022 4953 4928 4921>,
			<5390 5137 5018 4951 4927 4920>,
			<5384 5134 5016 4950 4926 4920>,
			<5383 5132 5015 4950 4926 4920>,
			<5390 5130 5016 4950 4927 4920>,
			<5401 5129 5016 4952 4928 4921>,
			<5414 5126 5017 4954 4929 4922>,
			<5433 5123 5018 4956 4931 4923>,
			<5454 5124 5019 4958 4932 4925>,
			<5478 5131 5021 4960 4935 4927>,
			<5504 5140 5021 4961 4936 4928>,
			<5533 5153 5022 4961 4934 4926>,
			<5564 5169 5022 4961 4933 4922>,
			<5597 5188 5024 4958 4930 4922>,
			<5631 5210 5026 4951 4927 4921>,
			<5667 5231 5028 4948 4927 4921>,
			<5704 5251 5031 4948 4927 4922>,
			<5742 5270 5036 4948 4926 4922>,
			<5784 5288 5045 4949 4925 4921>,
			<5830 5307 5054 4951 4926 4921>,
			<5863 5322 5051 4948 4922 4917>,
			<5951 5373 5068 4952 4926 4920>,
			<6010 5403 5079 4956 4927 4921>,
			<6086 5443 5095 4960 4929 4924>,
			<6184 5495 5112 4965 4933 4930>,
			<6309 5557 5133 4966 4935 4931>,
			<6513 5621 5153 4966 4929 4923>,
			<7076 5732 5183 4970 4930 4924>,
			<8242 5961 5244 4979 4934 4927>,
			<10651 6577 5342 5000 4945 4939>,
			<10651 6577 5342 5000 4945 4939>,
			<10651 6577 5342 5000 4945 4939>;
	};

};
